# STM32L4x6_v1r1 register map
File version: 1.1
CPU: CM4 r0p1, little endian, MPU, FPU, 4 interrupt priority bits
Registers are 32-bit, read-write, reset 0x0 unless marked. A register's access mark holds for its fields unless they carry their own. Offsets are from the block's base; [hi:lo] are bit positions.

## WWDG — System window watchdog
Base 0x40002C00
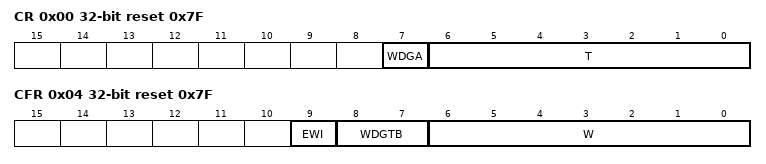
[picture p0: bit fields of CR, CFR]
0x00 CR reset 0x7F — Control register
  [7] WDGA — Activation bit
  [6:0] T — 7-bit counter (MSB to LSB)
0x04 CFR reset 0x7F — Configuration register
  [9] EWI — Early wakeup interrupt
  [8:7] WDGTB — Timer base
  [6:0] W — 7-bit window value
0x08 SR — Status register
  [0] EWIF — Early wakeup interrupt flag

## COMP — Comparator
Base 0x40010200
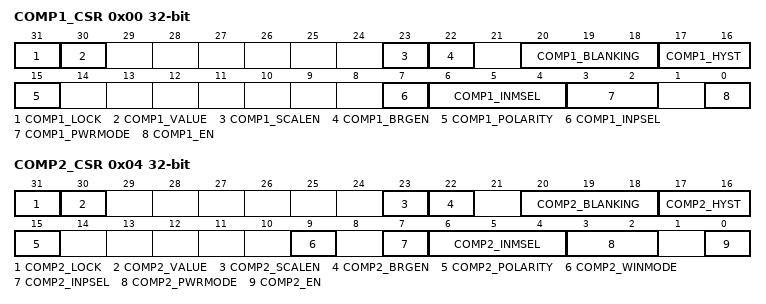
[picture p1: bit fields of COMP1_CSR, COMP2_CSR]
0x00 COMP1_CSR access per field — Comparator 1 control and status register
  [31] COMP1_LOCK wo — COMP1_CSR register lock bit
  [30] COMP1_VALUE ro — Comparator 1 output status bit
  [23] COMP1_SCALEN rw — Voltage scaler enable bit
  [22] COMP1_BRGEN rw — Scaler bridge enable
  [20:18] COMP1_BLANKING rw — Comparator 1 blanking source selection bits
  [17:16] COMP1_HYST rw — Comparator 1 hysteresis selection bits
  [15] COMP1_POLARITY rw — Comparator 1 polarity selection bit
  [7] COMP1_INPSEL rw — Comparator1 input plus selection bit
  [6:4] COMP1_INMSEL rw — Comparator 1 Input Minus connection configuration bit
  [3:2] COMP1_PWRMODE rw — Power Mode of the comparator 1
  [0] COMP1_EN rw — Comparator 1 enable bit
0x04 COMP2_CSR access per field — Comparator 2 control and status register
  [31] COMP2_LOCK wo — COMP2_CSR register lock bit
  [30] COMP2_VALUE ro — Comparator 2 output status bit
  [23] COMP2_SCALEN rw — Voltage scaler enable bit
  [22] COMP2_BRGEN rw — Scaler bridge enable
  [20:18] COMP2_BLANKING rw — Comparator 2 blanking source selection bits
  [17:16] COMP2_HYST rw — Comparator 2 hysteresis selection bits
  [15] COMP2_POLARITY rw — Comparator 2 polarity selection bit
  [9] COMP2_WINMODE rw — Windows mode selection bit
  [7] COMP2_INPSEL rw — Comparator 2 Input Plus connection configuration bit
  [6:4] COMP2_INMSEL rw — Comparator 2 Input Minus connection configuration bit
  [3:2] COMP2_PWRMODE rw — Power Mode of the comparator 2
  [0] COMP2_EN rw — Comparator 2 enable bit

## FIREWALL
Base 0x40011C00
0x00 CSSA — Code segment start address
  [23:8] ADD — code segment start address
0x04 CSL — Code segment length
  [21:8] LENG — code segment length
0x08 NVDSSA — Non-volatile data segment start address
  [23:8] ADD
0x0C NVDSL — Non-volatile data segment length
  [21:8] LENG
0x10 VDSSA — Volatile data segment start address
  [15:6] ADD
0x14 VDSL — Volatile data segment length
  [15:6] LENG — Non-volatile data segment length
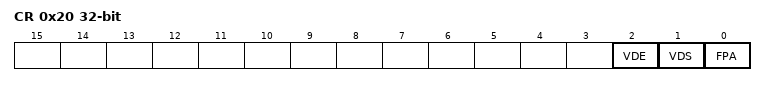
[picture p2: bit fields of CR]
0x20 CR — Configuration register
  [2] VDE — Volatile data execution
  [1] VDS — Volatile data shared
  [0] FPA — Firewall pre alarm

## DBGMCU — Debug support
Base 0xE0042000
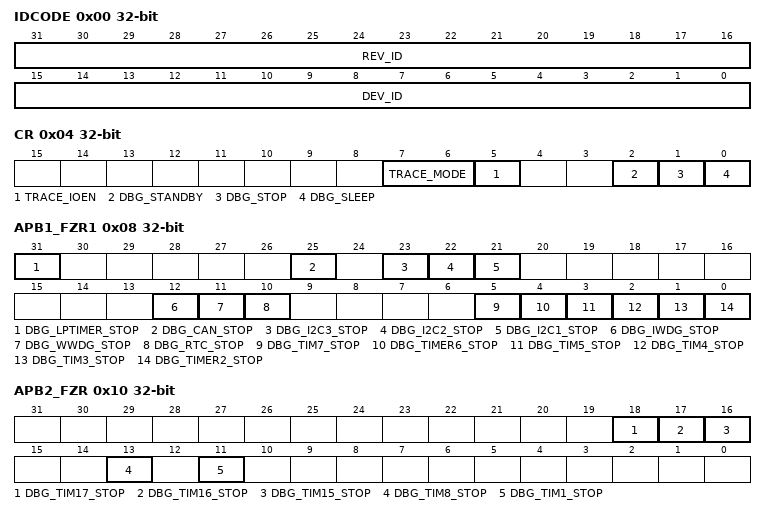
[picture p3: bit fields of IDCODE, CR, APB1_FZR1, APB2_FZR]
0x00 IDCODE ro — MCU Device ID Code Register
  [31:16] REV_ID — Revision Identifier
  [15:0] DEV_ID — Device Identifier
0x04 CR — Debug MCU Configuration Register
  [7:6] TRACE_MODE — Trace pin assignment control
  [5] TRACE_IOEN — Trace pin assignment control
  [2] DBG_STANDBY — Debug Standby Mode
  [1] DBG_STOP — Debug Stop Mode
  [0] DBG_SLEEP — Debug Sleep Mode
0x08 APB1_FZR1 — APB Low Freeze Register 1
  [31] DBG_LPTIMER_STOP — LPTIM1 counter stopped when core is halted
  [25] DBG_CAN_STOP — bxCAN stopped when core is halted
  [23] DBG_I2C3_STOP — I2C3 SMBUS timeout counter stopped when core is halted
  [22] DBG_I2C2_STOP — I2C2 SMBUS timeout mode stopped when core is halted
  [21] DBG_I2C1_STOP — I2C1 SMBUS timeout mode stopped when core is halted
  [12] DBG_IWDG_STOP — Debug Independent Wachdog stopped when Core is halted
  [11] DBG_WWDG_STOP — Debug Window Wachdog stopped when Core is halted
  [10] DBG_RTC_STOP — Debug RTC stopped when Core is halted
  [5] DBG_TIM7_STOP — TIM7 counter stopped when core is halted
  [4] DBG_TIMER6_STOP — Debug Timer 6 stopped when Core is halted
  [3] DBG_TIM5_STOP — TIM5 counter stopped when core is halted
  [2] DBG_TIM4_STOP — TIM4 counter stopped when core is halted
  [1] DBG_TIM3_STOP — TIM3 counter stopped when core is halted
  [0] DBG_TIMER2_STOP — Debug Timer 2 stopped when Core is halted
0x0C APB1_FZR2 — APB Low Freeze Register 2
  [5] DBG_LPTIM2_STOP — LPTIM2 counter stopped when core is halted
0x10 APB2_FZR — APB High Freeze Register
  [18] DBG_TIM17_STOP — TIM17 counter stopped when core is halted
  [17] DBG_TIM16_STOP — TIM16 counter stopped when core is halted
  [16] DBG_TIM15_STOP — TIM15 counter stopped when core is halted
  [13] DBG_TIM8_STOP — TIM8 counter stopped when core is halted
  [11] DBG_TIM1_STOP — TIM1 counter stopped when core is halted
